# STM32F215 register map
File version: 1.1
CPU: CM3 r1p1, little endian, no MPU, no FPU, 4 interrupt priority bits
Registers are 32-bit, read-write, reset 0x0 unless marked. A register's access mark holds for its fields unless they carry their own. Offsets are from the block's base; [hi:lo] are bit positions; {n}, {i} and the like mark numbered series.

## Ethernet_MAC — Ethernet: media access control (MAC)
Base 0x40028000
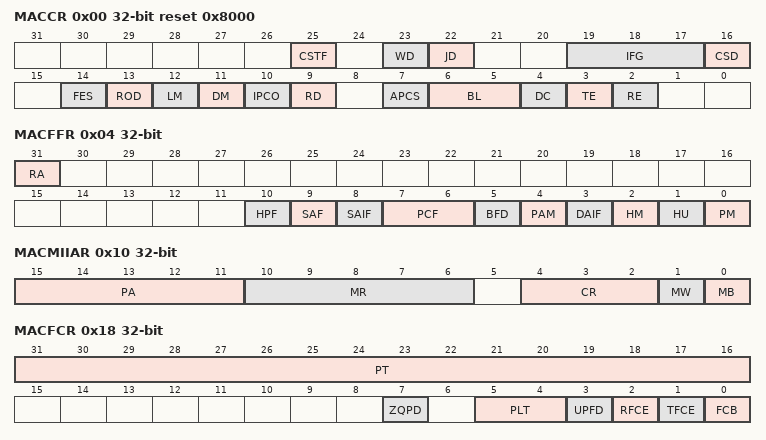
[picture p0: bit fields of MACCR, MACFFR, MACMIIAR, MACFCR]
0x00 MACCR reset 0x8000 — Ethernet MAC configuration register
  [25] CSTF, [23] WD, [22] JD, [19:17] IFG, [16] CSD, [14] FES, [13] ROD, [12] LM, [11] DM, [10] IPCO, [9] RD, [7] APCS, [6:5] BL, [4] DC, [3] TE, [2] RE
0x04 MACFFR — Ethernet MAC frame filter register
  [31] RA — Receive all
  [10] HPF — Hash or perfect filter
  [9] SAF — Source address filter
  [8] SAIF — Source address inverse filtering
  [7:6] PCF — Pass control frames
  [5] BFD — Broadcast frames disable
  [4] PAM — Pass all multicast
  [3] DAIF — Destination address inverse filtering
  [2] HM — Hash multicast
  [1] HU — Hash unicast
  [0] PM — Promiscuous mode
0x08 MACHTHR — Ethernet MAC hash table high register
  [31:0] HTH — Hash table high
0x0C MACHTLR — Ethernet MAC hash table low register
  [31:0] HTL — Hash table low
0x10 MACMIIAR — Ethernet MAC MII address register
  [15:11] PA — PHY address
  [10:6] MR — MII register
  [4:2] CR — Clock range
  [1] MW — MII write
  [0] MB — MII busy
0x14 MACMIIDR — Ethernet MAC MII data register
  [15:0] MD — MII data
0x18 MACFCR — Ethernet MAC flow control register
  [31:16] PT — Pause time
  [7] ZQPD — Zero-quanta pause disable
  [5:4] PLT — Pause low threshold
  [3] UPFD — Unicast pause frame detect
  [2] RFCE — Receive flow control enable
  [1] TFCE — Transmit flow control enable
  [0] FCB — Flow control busy/back pressure activate
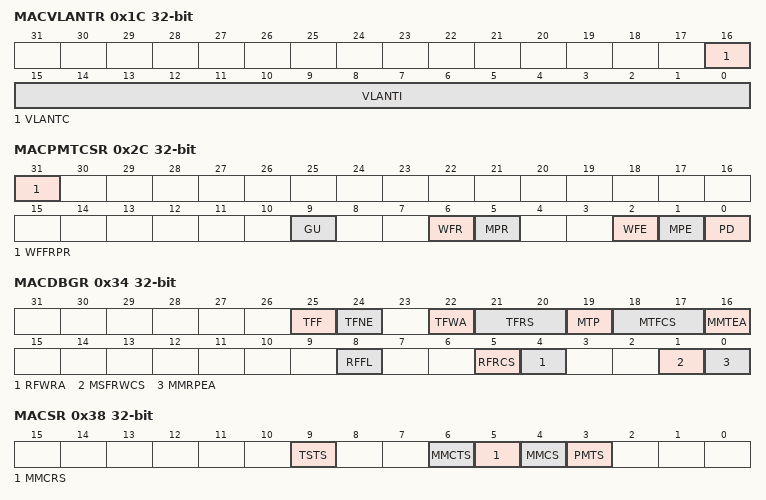
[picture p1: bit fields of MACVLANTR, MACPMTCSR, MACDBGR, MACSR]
0x1C MACVLANTR — Ethernet MAC VLAN tag register
  [16] VLANTC — 12-bit VLAN tag comparison
  [15:0] VLANTI — VLAN tag identifier
0x28 MACRWUFFR — Ethernet MAC remote wakeup frame filter register
0x2C MACPMTCSR — Ethernet MAC PMT control and status register
  [31] WFFRPR — Wakeup frame filter register pointer reset
  [9] GU — Global unicast
  [6] WFR — Wakeup frame received
  [5] MPR — Magic packet received
  [2] WFE — Wakeup frame enable
  [1] MPE — Magic Packet enable
  [0] PD — Power down
0x34 MACDBGR ro — Ethernet MAC debug register
  [25] TFF — Tx FIFO full
  [24] TFNE — Tx FIFO not empty
  [22] TFWA — Tx FIFO write active
  [21:20] TFRS — Tx FIFO read status
  [19] MTP — MAC transmitter in pause
  [18:17] MTFCS — MAC transmit frame controller status
  [16] MMTEA — MAC MII transmit engine active
  [8] RFFL — Rx FIFO fill level
  [5] RFRCS — Rx FIFO read controller status
  [4] RFWRA — Rx FIFO write controller active
  [1] MSFRWCS — MAC small FIFO read / write controllers status
  [0] MMRPEA — MAC MII receive protocol engine active
0x38 MACSR access per field — Ethernet MAC interrupt status register
  [9] TSTS rw — Time stamp trigger status
  [6] MMCTS ro — MMC transmit status
  [5] MMCRS ro — MMC receive status
  [4] MMCS ro — MMC status
  [3] PMTS ro — PMT status
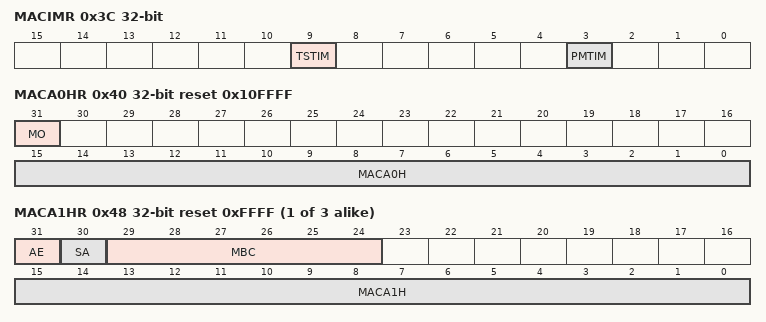
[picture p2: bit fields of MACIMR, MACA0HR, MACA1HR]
0x3C MACIMR — Ethernet MAC interrupt mask register
  [9] TSTIM — Time stamp trigger interrupt mask
  [3] PMTIM — PMT interrupt mask
0x40 MACA0HR access per field reset 0x10FFFF — Ethernet MAC address 0 high register
  [31] MO ro
  [15:0] MACA0H rw — MAC address0 high
0x44 MACA0LR reset 0xFFFFFFFF — Ethernet MAC address 0 low register
  [31:0] MACA0L — MAC address0 low
{0x40+8i} MACA{i}HR reset 0xFFFF (i=1..3) — Ethernet MAC address {i} high register
  [31] AE — Address enable
  [30] SA — Source address
  [29:24] MBC — Mask byte control
  [15:0] MACA{i}H — MAC address{i} high
0x4C MACA1LR reset 0xFFFFFFFF — Ethernet MAC address1 low register
  [31:0] MACA1L — MAC address1 low
0x54 MACA2LR reset 0xFFFFFFFF — Ethernet MAC address 2 low register
  [31:0] MACA2L — MAC address2 low
0x5C MACA3LR reset 0xFFFFFFFF — Ethernet MAC address 3 low register
  [31:0] MACA3L — MAC address3 low

## Ethernet_MMC — Ethernet: MAC management counters
Base 0x40028100
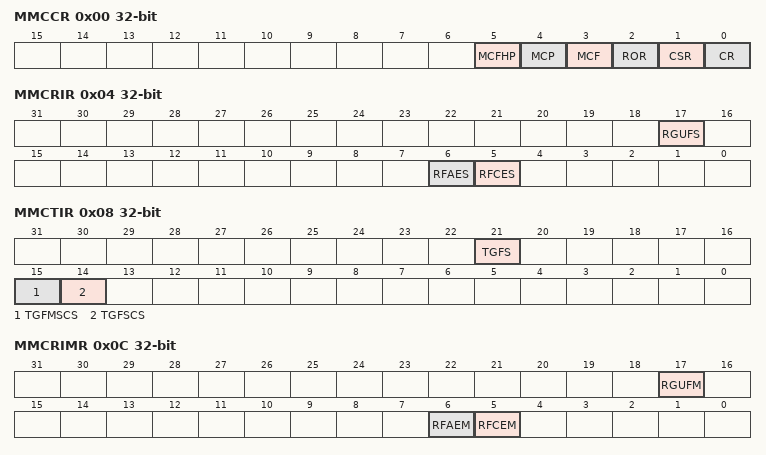
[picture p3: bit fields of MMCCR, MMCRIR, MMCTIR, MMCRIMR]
0x00 MMCCR — Ethernet MMC control register
  [5] MCFHP — MMC counter Full-Half preset
  [4] MCP — MMC counter preset
  [3] MCF — MMC counter freeze
  [2] ROR — Reset on read
  [1] CSR — Counter stop rollover
  [0] CR — Counter reset
0x04 MMCRIR — Ethernet MMC receive interrupt register
  [17] RGUFS — Received Good Unicast Frames Status
  [6] RFAES — Received frames alignment error status
  [5] RFCES — Received frames CRC error status
0x08 MMCTIR — Ethernet MMC transmit interrupt register
  [21] TGFS — Transmitted good frames status
  [15] TGFMSCS — Transmitted good frames more single collision status
  [14] TGFSCS — Transmitted good frames single collision status
0x0C MMCRIMR — Ethernet MMC receive interrupt mask register
  [17] RGUFM — Received good unicast frames mask
  [6] RFAEM — Received frames alignment error mask
  [5] RFCEM — Received frame CRC error mask
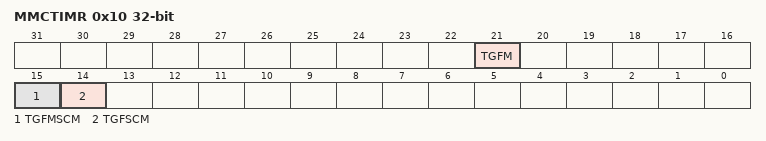
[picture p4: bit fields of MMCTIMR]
0x10 MMCTIMR — Ethernet MMC transmit interrupt mask register
  [21] TGFM — Transmitted good frames mask
  [15] TGFMSCM — Transmitted good frames more single collision mask
  [14] TGFSCM — Transmitted good frames single collision mask
0x4C MMCTGFSCCR ro — Ethernet MMC transmitted good frames after a single collision counter
  [31:0] TGFSCC — Transmitted good frames single collision counter
0x50 MMCTGFMSCCR ro — Ethernet MMC transmitted good frames after more than a single collision
  [31:0] TGFMSCC — Transmitted good frames more single collision counter
0x68 MMCTGFCR ro — Ethernet MMC transmitted good frames counter register
  [31:0] TGFC — Transmitted good frames counter
0x94 MMCRFCECR ro — Ethernet MMC received frames with CRC error counter register
  [31:0] RFCFC — Received frames CRC error counter
0x98 MMCRFAECR ro — Ethernet MMC received frames with alignment error counter register
  [31:0] RFAEC — Received frames alignment error counter
0xC4 MMCRGUFCR ro — MMC received good unicast frames counter register
  [31:0] RGUFC — Received good unicast frames counter
